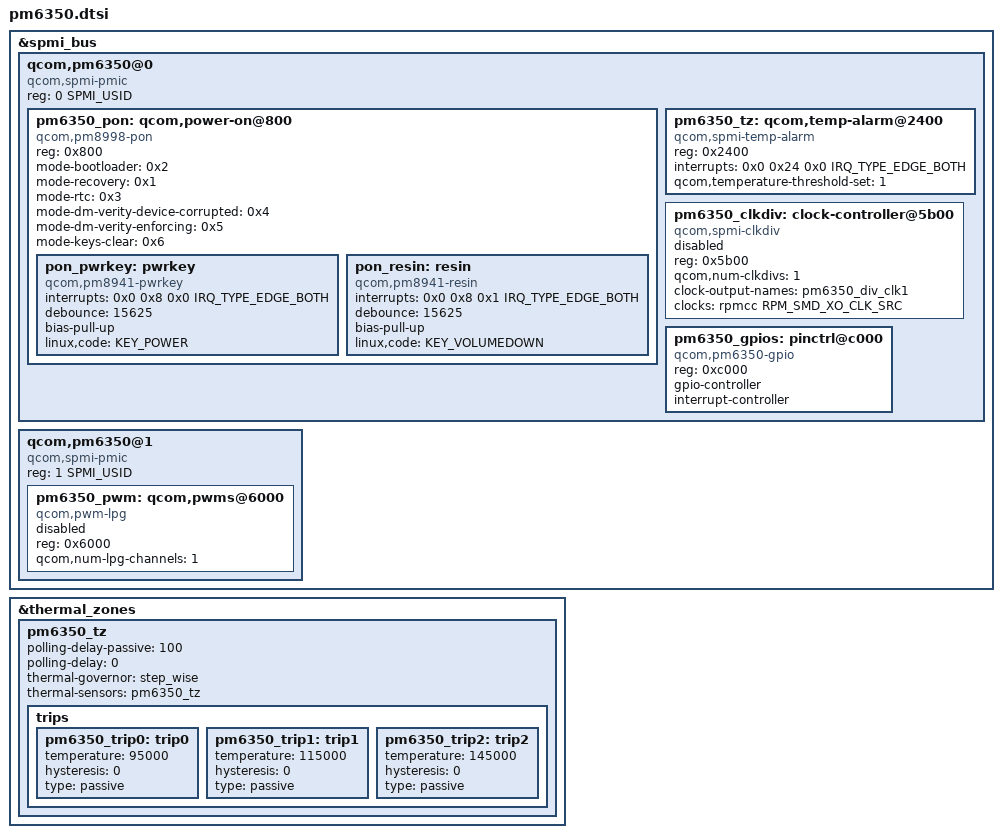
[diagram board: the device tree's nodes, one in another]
#include <dt-bindings/clock/qcom,rpmcc.h>
#include <dt-bindings/input/input.h>
#include <dt-bindings/input/qcom,qpnp-power-on.h>
#include <dt-bindings/spmi/spmi.h>

&spmi_bus {
	qcom,pm6350@0 {
		compatible = "qcom,spmi-pmic";
		reg = <0 SPMI_USID>;
		#address-cells = <1>;
		#size-cells = <0>;

		pm6350_pon: qcom,power-on@800 {
			compatible = "qcom,pm8998-pon";
			reg = <0x800>;
			mode-bootloader = <0x2>;
			mode-recovery = <0x1>;
			mode-rtc = <0x3>;
			mode-dm-verity-device-corrupted = <0x4>;
			mode-dm-verity-enforcing = <0x5>;
			mode-keys-clear = <0x6>;

			pon_pwrkey: pwrkey {
				compatible = "qcom,pm8941-pwrkey";
				interrupts = <0x0 0x8 0x0 IRQ_TYPE_EDGE_BOTH>;
				debounce = <15625>;
				bias-pull-up;
				linux,code = <KEY_POWER>;
			};

			pon_resin: resin {
				compatible = "qcom,pm8941-resin";
				interrupts = <0x0 0x8 0x1 IRQ_TYPE_EDGE_BOTH>;
				debounce = <15625>;
				bias-pull-up;
				linux,code = <KEY_VOLUMEDOWN>;
			};
		};

		pm6350_tz: qcom,temp-alarm@2400 {
			compatible = "qcom,spmi-temp-alarm";
			reg = <0x2400>;
			interrupts = <0x0 0x24 0x0 IRQ_TYPE_EDGE_BOTH>;
			#thermal-sensor-cells = <0>;
			qcom,temperature-threshold-set = <1>;
		};

		pm6350_clkdiv: clock-controller@5b00 {
			compatible = "qcom,spmi-clkdiv";
			reg = <0x5b00>;
			#clock-cells = <1>;
			qcom,num-clkdivs = <1>;
			clock-output-names = "pm6350_div_clk1";
			clocks = <&rpmcc RPM_SMD_XO_CLK_SRC>;
			clock-names = "xo";
			status = "disabled";
		};

		pm6350_gpios: pinctrl@c000 {
			compatible = "qcom,pm6350-gpio";
			reg = <0xc000>;
			gpio-controller;
			#gpio-cells = <2>;
			interrupt-controller;
			#interrupt-cells = <2>;
		};
	};

	qcom,pm6350@1 {
		compatible ="qcom,spmi-pmic";
		reg = <1 SPMI_USID>;
		#address-cells = <1>;
		#size-cells = <0>;

		pm6350_pwm: qcom,pwms@6000 {
			status = "disabled";
			compatible = "qcom,pwm-lpg";
			reg = <0x6000>;
			reg-names = "lpg-base";
			qcom,num-lpg-channels = <1>;
			#pwm-cells = <2>;
		};
	};
};

&thermal_zones {
	pm6350_tz {
		polling-delay-passive = <100>;
		polling-delay = <0>;
		thermal-governor = "step_wise";
		thermal-sensors = <&pm6350_tz>;

		trips {
			pm6350_trip0: trip0 {
				temperature = <95000>;
				hysteresis = <0>;
				type = "passive";
			};

			pm6350_trip1: trip1 {
				temperature = <115000>;
				hysteresis = <0>;
				type = "passive";
			};

			pm6350_trip2: trip2 {
				temperature = <145000>;
				hysteresis = <0>;
				type = "passive";
			};
		};
	};
};
